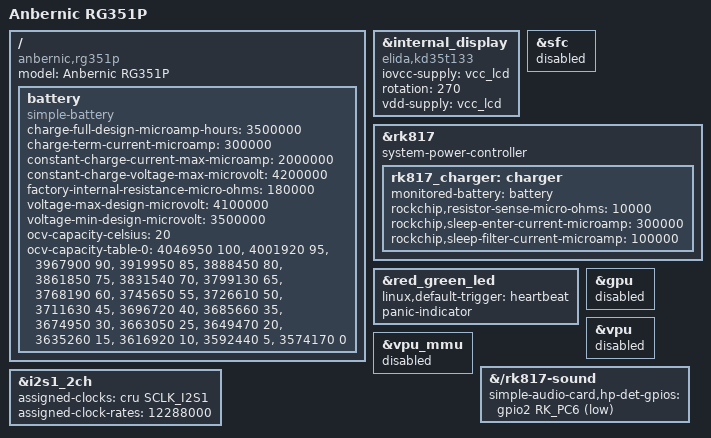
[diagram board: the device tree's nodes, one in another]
// SPDX-License-Identifier: (GPL-2.0+ OR MIT)
/*
 * Anbernic RG351P
 *
 * The RG351P shares its mainboard with the RG351M (metal shell variant),
 * so reuse the mainline RG351M board description and only override what
 * differs. Built out of tree, see mk/linux.mk.
 */

/dts-v1/;
#include "rk3326-anbernic-rg351m.dtsi"

/ {
	model = "Anbernic RG351P";
	compatible = "anbernic,rg351p", "rockchip,rk3326";
};

/* Same panel as the RG351M, mounted in portrait orientation */
&internal_display {
	compatible = "elida,kd35t133";
	iovcc-supply = <&vcc_lcd>;
	rotation = <270>;
	vdd-supply = <&vcc_lcd>;
};

/*
 * No SPI NOR flash on the RG351P (the vendor BSP DTS disables sfc too).
 * The mainline node is inherited from the Odroid Go Advance; disabling it
 * avoids a useless probe at boot.
 */
&sfc {
	status = "disabled";
};

/*
 * Let the RK817 cut power on poweroff. Without this property the kernel
 * falls back to PSCI SYSTEM_OFF, which is not guaranteed to turn the
 * PMIC off (mainline OGA/RG351M DTs lack it, rk3326-gameforce-chi has it).
 */
&rk817 {
	system-power-controller;
};

/*
 * Bring-up aid: heartbeat once the LED driver probes, steady blinking on
 * panic. Needs the LED triggers from debug.config, ignored otherwise.
 */
&red_green_led {
	linux,default-trigger = "heartbeat";
	panic-indicator;
};

/*
 * No GPU or video codec driver is built (frames are rendered by the CPU).
 * Leaving the nodes enabled keeps their power domains on forever, since
 * the PM domain driver waits in sync_state() for consumers that never bind.
 */
&gpu {
	status = "disabled";
};

&vpu {
	status = "disabled";
};

&vpu_mmu {
	status = "disabled";
};

/*
 * Battery and charger (RK817). Mainline dropped the charger when the
 * RG351M was split from the Odroid Go Advance, so nothing bound to
 * CONFIG_CHARGER_RK817; this restores it as rk3326-odroid-go.dtsi has it.
 *
 * Sense resistor: the vendor BSP DTS for the RG351P (AmberELEC
 * rk3326-rg351p-linux.dts) says sample_res = <10> (10 mOhm), like the OGA
 * schematic. ROCKNIX's RG351M/V DTs say "no current sense resistor" but
 * still end up with 10 mOhm (inherited, or <0>, which the driver treats
 * like 10000: it only distinguishes 20000). The RK817 needs the resistor
 * to regulate the charge current, so 10 mOhm it is.
 *
 * Battery: 3500 mAh per Anbernic and ROCKNIX (BSP: design_capacity 3450,
 * KPL605475 cell, 4.2 V charge, 180 mOhm). Charge current 2 A and
 * termination 300 mA as in the BSP charger node and the OGA DT. The OCV
 * table is the one mainline uses for the OGA (rk3326-odroid-go2.dts),
 * which ROCKNIX also ships for the RG351M/V. Voltage limits as there.
 */
/ {
	battery: battery {
		compatible = "simple-battery";
		charge-full-design-microamp-hours = <3500000>;
		charge-term-current-microamp = <300000>;
		constant-charge-current-max-microamp = <2000000>;
		constant-charge-voltage-max-microvolt = <4200000>;
		factory-internal-resistance-micro-ohms = <180000>;
		voltage-max-design-microvolt = <4100000>;
		voltage-min-design-microvolt = <3500000>;

		ocv-capacity-celsius = <20>;
		ocv-capacity-table-0 =  <4046950 100>, <4001920 95>, <3967900 90>, <3919950 85>,
					<3888450 80>, <3861850 75>, <3831540 70>, <3799130 65>,
					<3768190 60>, <3745650 55>, <3726610 50>, <3711630 45>,
					<3696720 40>, <3685660 35>, <3674950 30>, <3663050 25>,
					<3649470 20>, <3635260 15>, <3616920 10>, <3592440 5>,
					<3574170 0>;
	};
};

&rk817 {
	rk817_charger: charger {
		monitored-battery = <&battery>;
		rockchip,resistor-sense-micro-ohms = <10000>;
		rockchip,sleep-enter-current-microamp = <300000>;
		rockchip,sleep-filter-current-microamp = <100000>;
	};
};

/*
 * Sound (RK817 codec on i2s1_2ch via simple-audio-card).
 *
 * Headphone detect: the RG351P jack switch pulls GPIO2_PC6 low when a
 * plug is in. The vendor BSP DT (rk3326-rg351p-linux.dts) has
 * GPIO_ACTIVE_LOW; the inherited RG351M dtsi says ACTIVE_HIGH and
 * reported "inserted" at boot with nothing plugged in. The hp_det pinctrl
 * of the dtsi (pull-down) is deliberately not referenced: with an active
 * low switch it would read as inserted when nothing is plugged in.
 *
 * MCLK: simple-card sets the codec clock (SCLK_I2S1_OUT) first on the
 * first hw_params. Its mux has no CLK_SET_RATE_PARENT, so it picks the
 * fastest parent at or below 12.288 MHz from the current rates: xin12m
 * (12.000 MHz) unless clk_i2s1 already runs at 12.288 MHz. The codec
 * would then get 12 MHz while the I2S runs from 12.288 MHz until the
 * next hw_params. Starting clk_i2s1 at 256 x 48 kHz avoids that.
 */
&{/rk817-sound} {
	simple-audio-card,hp-det-gpios = <&gpio2 RK_PC6 GPIO_ACTIVE_LOW>;
};

&i2s1_2ch {
	assigned-clocks = <&cru SCLK_I2S1>;
	assigned-clock-rates = <12288000>;
};
